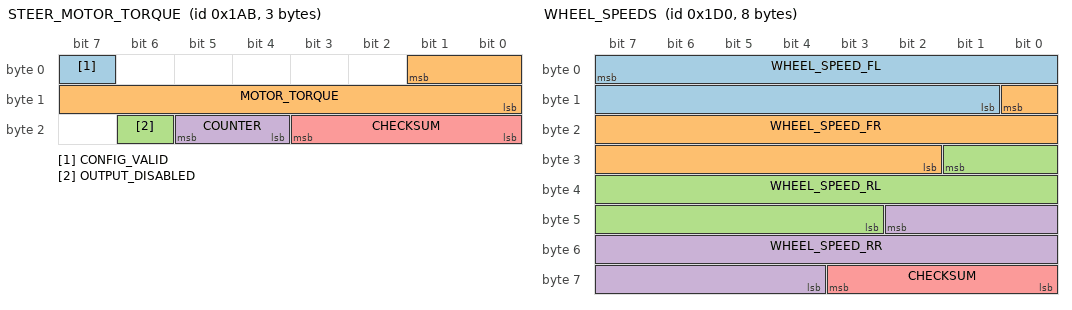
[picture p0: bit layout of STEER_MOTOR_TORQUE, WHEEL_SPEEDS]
BO_ 427 STEER_MOTOR_TORQUE: 3 EPS
 SG_ CONFIG_VALID : 7|1@0+ (1,0) [0|1] "" EON
 SG_ MOTOR_TORQUE : 1|10@0+ (1,0) [0|256] "" EON
 SG_ OUTPUT_DISABLED : 22|1@0+ (1,0) [0|1] "" EON
 SG_ COUNTER : 21|2@0+ (1,0) [0|3] "" EON
 SG_ CHECKSUM : 19|4@0+ (1,0) [0|15] "" EON

BO_ 464 WHEEL_SPEEDS: 8 VSA
 SG_ WHEEL_SPEED_FL : 7|15@0+ (0.01,0) [0|250] "kph" EON
 SG_ WHEEL_SPEED_FR : 8|15@0+ (0.01,0) [0|250] "kph" EON
 SG_ WHEEL_SPEED_RL : 25|15@0+ (0.01,0) [0|250] "kph" EON
 SG_ WHEEL_SPEED_RR : 42|15@0+ (0.01,0) [0|250] "kph" EON
 SG_ CHECKSUM : 59|4@0+ (1,0) [0|3] "" EON
